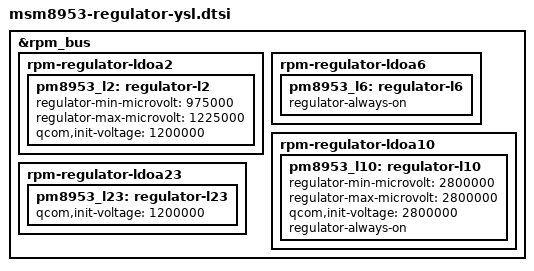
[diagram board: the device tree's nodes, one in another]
/*
 * Copyright (c) 2015-2016, The Linux Foundation. All rights reserved.
 * Copyright (C) 2019 XiaoMi, Inc.
 *
 * This program is free software; you can redistribute it and/or modify
 * it under the terms of the GNU General Public License version 2 and
 * only version 2 as published by the Free Software Foundation.
 *
 * This program is distributed in the hope that it will be useful,
 * but WITHOUT ANY WARRANTY; without even the implied warranty of
 * MERCHANTABILITY or FITNESS FOR A PARTICULAR PURPOSE.  See the
 * GNU General Public License for more details.
 */

#include <dt-bindings/interrupt-controller/arm-gic.h>

&rpm_bus {
	rpm-regulator-ldoa2 {
		pm8953_l2: regulator-l2 {
			regulator-min-microvolt = <975000>;
			regulator-max-microvolt = <1225000>;
			qcom,init-voltage = <1200000>;
			status = "okay";
		};
	};
	rpm-regulator-ldoa6 {
		pm8953_l6: regulator-l6 {
 			regulator-always-on;
		};
	};
	rpm-regulator-ldoa10 {
		status = "okay";
		pm8953_l10: regulator-l10 {
			regulator-min-microvolt = <2800000>;
			regulator-max-microvolt = <2800000>;
			qcom,init-voltage = <2800000>;
			regulator-always-on;
		};
	};
	rpm-regulator-ldoa23 {
 		pm8953_l23: regulator-l23 {
 			qcom,init-voltage = <1200000>;
		};
	};
};
